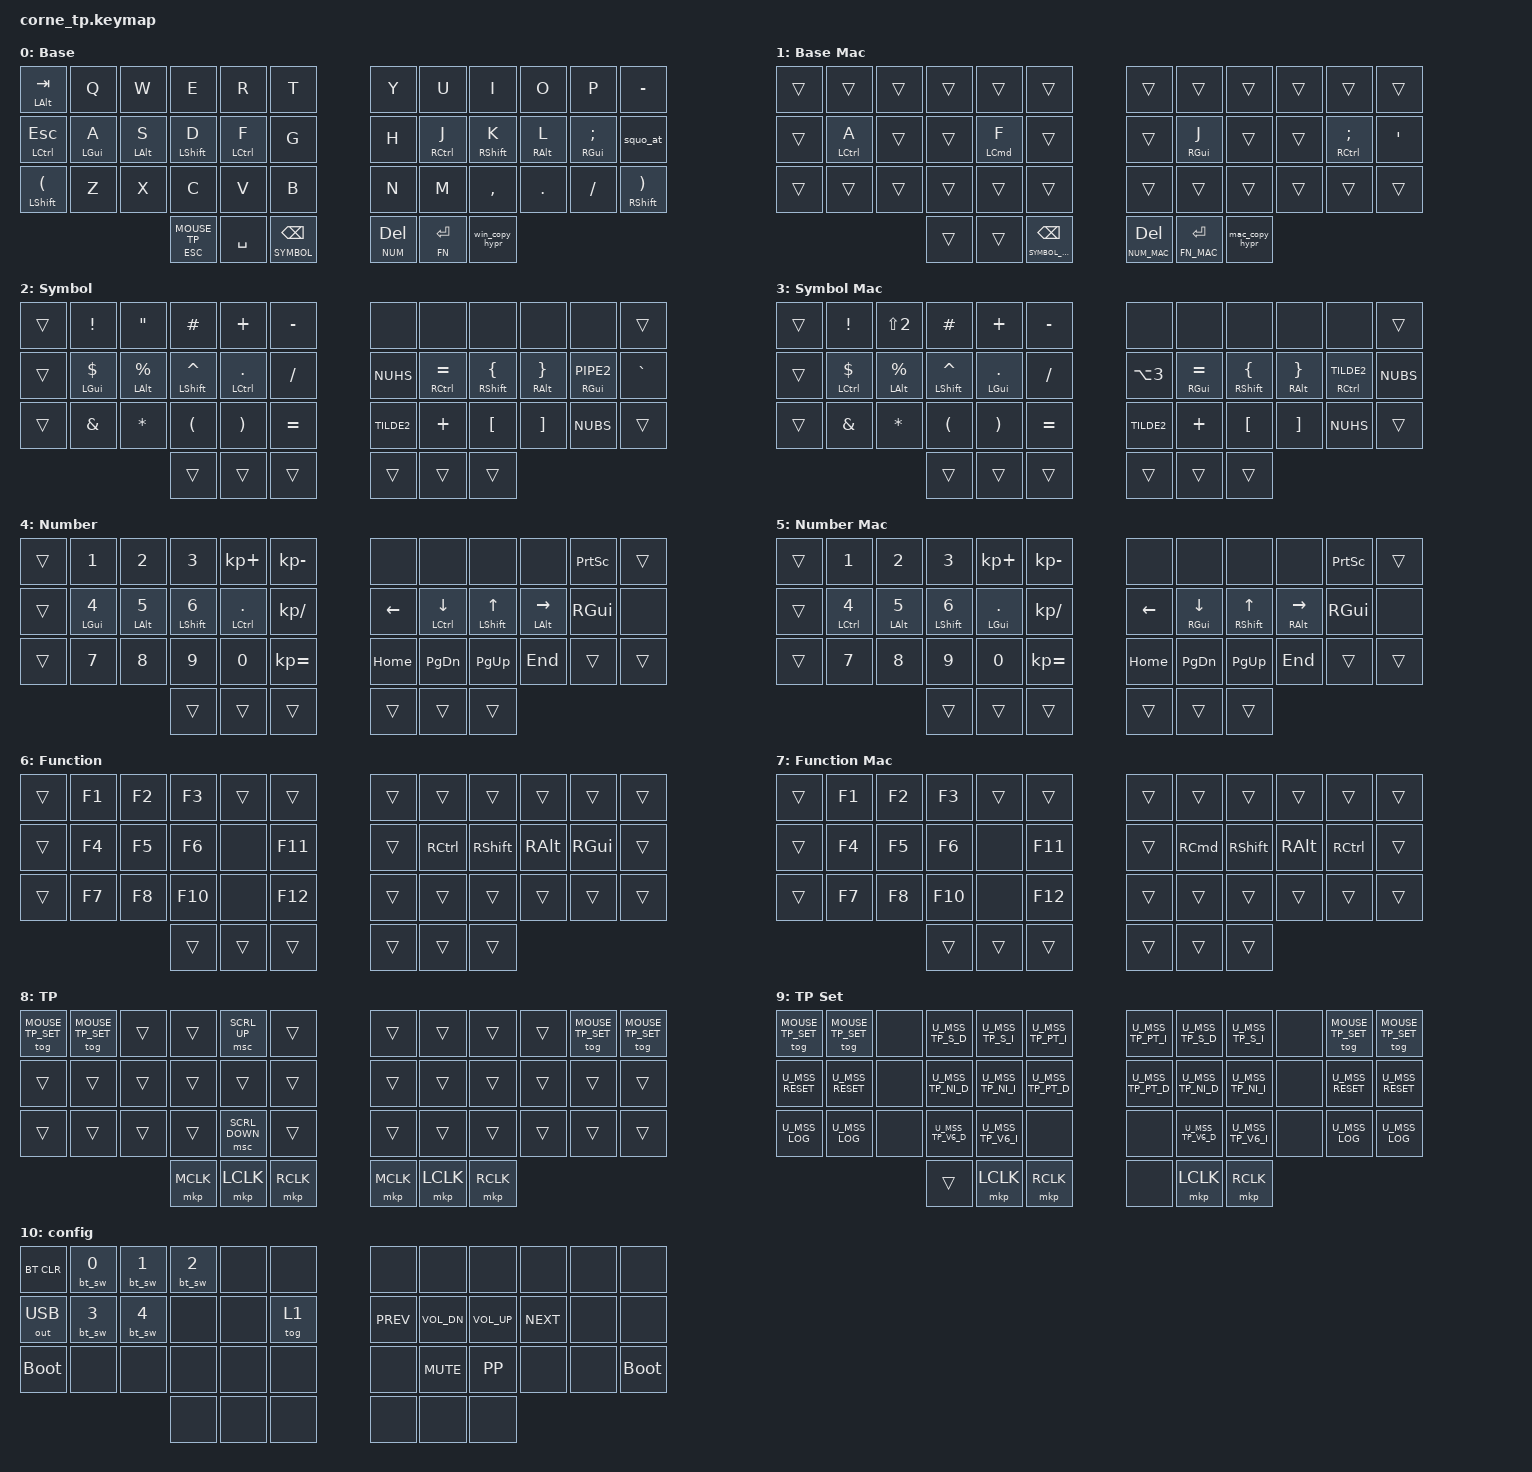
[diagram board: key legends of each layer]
/*
 * Copyright (c) 2020 The ZMK Contributors
 *
 * SPDX-License-Identifier: MIT
 */

#include <behaviors.dtsi>
#include <dt-bindings/zmk/keys.h>
#include <dt-bindings/zmk/bt.h>
#include <dt-bindings/zmk/outputs.h>

#define BASE 0
#define BASE_MAC 1
#define SYMBOL 2
#define SYMBOL_MAC 3
#define NUM 4
#define NUM_MAC 5
#define FN 6
#define FN_MAC 7
#define MOUSE_TP 8
#define MOUSE_TP_SET 9
#define CONFIG 10

/*
 * Defines to enable/disable features
 *
 * These defines allow us to conditionally enable and disable parts of the keymap config.
 *
 * For example, if we decide to build the firmware without the mouse features, we can
 * disable all the config options that rely on those forks and modules without having
 * to edit the entire keymap file manually every time.
 */

#define HAS_MOUSE_KEYS
#define HAS_MOUSE_TP

#ifdef HAS_MOUSE_KEYS
  #include <dt-bindings/zmk/mouse.h>
  #include <behaviors/mouse_keys.dtsi>
#endif  // HAS_MOUSE_KEYS

#ifdef HAS_MOUSE_TP
  // We store the trackpoint settings in a separate file
  // to make organization a little easier.
  #include "include/mouse_tp.dtsi"
#endif  // HAS_MOUSE_TP



// Adjust layer keys based on enabled features.
//
// This prevents build errors when we build the firmware
// without the mouse keys PR or the TP module.
#ifdef HAS_MOUSE_KEYS
  #define U_THUMB_INNER &mo MOUSE_KEYS
#else
  #define U_THUMB_INNER &none
#endif  // HAS_MOUSE_KEYS

#ifdef HAS_MOUSE_TP
  #define U_TOG_TP_SET &tog MOUSE_TP_SET
#else
  #define U_TOG_TP_SET &none
#endif  // HAS_MOUSE_TP

&mt {
    flavor = "tap-preferred";
    require-prior-idle-ms = <100>;
    quick-tap-ms = <80>;
};

&lt {
    quick-tap-ms = <80>;
    require-prior-idle-ms = <0>;
    flavor = "hold-preferred";
};
// Disable line-wrap in your editor to see a "visualization" of the key layouts
/ {
     behaviors {
        squo_at: squo_at {
            compatible = "zmk,behavior-mod-morph";
            label = "SQUO_AT";
            bindings = <&kp SQT>, <&kp LS(N2)>;

            #binding-cells = <0>;
            mods = <(MOD_LSFT|MOD_RSFT)>;
        };

        win_copy_hypr: win_copy_hypr {
            compatible = "zmk,behavior-tap-dance";
            label = "WIN_COPY_HYPR";
            #binding-cells = <0>;
            bindings = <&mt LS(LA(LC(LGUI))) LC(C)>, <&kp LC(V)>;
        };

        mac_copy_hypr: mac_copy_hypr {
            compatible = "zmk,behavior-tap-dance";
            label = "MAC_COPY_HYPR";
            #binding-cells = <0>;
            bindings = <&mt LS(LA(LC(LGUI))) LG(C)>, <&kp LG(V)>;
        };

        squo_at_mac: squo_at_mac {
            compatible = "zmk,behavior-mod-morph";
            label = "SQUO_AT_MAC";
            bindings = <&kp SQT>, <&kp N2>;

            #binding-cells = <0>;
            mods = <(MOD_LSFT|MOD_RSFT)>;
        };
    };

    macros {
        bt_sw: bt_sw {
            compatible = "zmk,behavior-macro-one-param";
            #binding-cells = <1>;
            bindings = <&out OUT_BLE>, <&macro_param_1to2>, <&bt BT_SEL MACRO_PLACEHOLDER>;
            label = "BT_SW";
        };
    };
     
     conditional_layers {
        compatible = "zmk,conditional-layers";

        config_layer {
            if-layers = <SYMBOL NUM>;
            then-layer = <CONFIG>;
        };

        config_layer_mac {
            if-layers = <SYMBOL_MAC NUM_MAC>;
            then-layer = <CONFIG>;
        };
    };

  keymap {
    compatible = "zmk,keymap";

    base {
     display-name = "Base";
                 bindings = <
&mt LALT TAB    &kp Q       &kp W       &kp E        &kp R        &kp T              &kp Y         &kp U        &kp I           &kp O       &kp P          &kp MINUS
&mt LCTRL ESC   &mt LGUI A  &mt LALT S  &mt LSHFT D  &mt LCTRL F  &kp G              &kp H         &mt RCTRL J  &mt RSHFT K     &mt RALT L  &mt RGUI SEMI  &squo_at
&mt LSHFT LPAR  &kp Z       &kp X       &kp C        &kp V        &kp B              &kp N         &kp M        &kp COMMA       &kp DOT     &kp FSLH       &mt RSHFT RPAR
                                        &lt ESC MOUSE_TP      &kp SPACE    &lt SYMBOL BACKSPACE    &lt NUM DELETE  &lt FN ENTER  &win_copy_hypr
            >;
    };

    base_mac {
     display-name = "Base Mac";
                 bindings = <
&trans  &trans       &trans  &trans  &trans      &trans             &trans     &trans       &trans          &trans  &trans               &trans
&trans  &mt LCTRL A  &trans  &trans  &mt LCMD F  &trans             &trans     &mt RGUI J   &trans          &trans  &mt RCTRL SEMICOLON  &kp SINGLE_QUOTE
&trans  &trans       &trans  &trans  &trans      &trans             &trans     &trans       &trans          &trans  &trans               &trans
                             &trans  &trans      &lt SYMBOL_MAC BACKSPACE    &lt NUM_MAC DEL  &lt FN_MAC ENTER  &mac_copy_hypr
            >;
    };

    symbol {
     display-name = "Symbol";
                 bindings = <
&trans  &kp EXCL       &kp DQT &kp HASH              &kp PLUS       &kp MINUS    &none       &none            &none           &none          &none           &trans
&trans  &mt LGUI DLLR  &mt LALT PRCNT    &mt LEFT_SHIFT CARET  &mt LCTRL DOT  &kp FSLH     &kp NUHS    &mt RCTRL EQUAL  &mt RSHFT LBRC  &mt RALT RBRC  &mt RGUI PIPE2  &kp GRAVE
&trans  &kp AMPS       &kp STAR          &kp LPAR              &kp RPAR       &kp EQUAL    &kp TILDE2  &kp PLUS         &kp LBKT        &kp RBKT       &kp NUBS        &trans
                                         &trans                &trans         &trans       &trans      &trans           &trans
            >;
    };

    symbol_mac {
     display-name = "Symbol Mac";
            bindings = <
&trans  &kp EXCL        &kp LS(NUMBER_2)  &kp HASH              &kp PLUS      &kp MINUS    &none       &none           &none           &none          &none             &trans
&trans  &mt LCTRL DLLR  &mt LALT PRCNT     &mt LEFT_SHIFT CARET  &mt LGUI DOT  &kp FSLH     &kp LA(N3)  &mt RGUI EQUAL  &mt RSHFT LBRC  &mt RALT RBRC  &mt RCTRL TILDE2  &kp NUBS
&trans  &kp AMPS        &kp STAR           &kp LPAR              &kp RPAR      &kp EQUAL    &kp TILDE2  &kp PLUS        &kp LBKT        &kp RBKT       &kp NUHS          &trans
                                           &trans                &trans        &trans       &trans      &trans          &trans
            >;
    };

    number {
     display-name = "Number";
                 bindings = <
&trans  &kp N1       &kp N2       &kp N3         &kp KP_PLUS    &kp KP_MINUS    &none     &none           &none          &none               &kp PRINTSCREEN  &trans
&trans  &mt LGUI N4  &mt LALT N5  &mt LSHIFT N6  &mt LCTRL DOT  &kp KP_SLASH    &kp LEFT  &mt LCTRL DOWN  &mt LSHIFT UP  &mt LEFT_ALT RIGHT  &kp RGUI         &none
&trans  &kp N7       &kp N8       &kp N9         &kp N0         &kp KP_EQUAL    &kp HOME  &kp PG_DN       &kp PG_UP      &kp END             &trans           &trans
                                  &trans         &trans         &trans          &trans    &trans          &trans
            >;
    };

    number_mac {
     display-name = "Number Mac";
                 bindings = <
&trans  &kp N1        &kp N2       &kp N3         &kp KP_PLUS   &kp KP_MINUS    &none     &none          &none          &none           &kp PRINTSCREEN  &trans
&trans  &mt LCTRL N4  &mt LALT N5  &mt LSHIFT N6  &mt LGUI DOT  &kp KP_SLASH    &kp LEFT  &mt RGUI DOWN  &mt RSHIFT UP  &mt RALT RIGHT  &kp RGUI         &none
&trans  &kp N7        &kp N8       &kp N9         &kp N0        &kp KP_EQUAL    &kp HOME  &kp PG_DN      &kp PG_UP      &kp END         &trans           &trans
                                   &trans         &trans        &trans          &trans    &trans         &trans
            >;
    };

    fn {
     display-name = "Function";
                 bindings = <
&trans  &kp F1  &kp F2  &kp F3   &trans  &trans     &trans  &trans     &trans     &trans    &trans    &trans
&trans  &kp F4  &kp F5  &kp F6   &none   &kp F11    &trans  &kp RCTRL  &kp RSHFT  &kp RALT  &kp RGUI  &trans
&trans  &kp F7  &kp F8  &kp F10  &none   &kp F12    &trans  &trans     &trans     &trans    &trans    &trans
                        &trans   &trans  &trans     &trans  &trans     &trans
            >;
    };

    fn_mac {
     display-name = "Function Mac";
                 bindings = <
&trans  &kp F1  &kp F2  &kp F3   &trans  &trans     &trans  &trans    &trans     &trans    &trans     &trans
&trans  &kp F4  &kp F5  &kp F6   &none   &kp F11    &trans  &kp RCMD  &kp RSHFT  &kp RALT  &kp RCTRL  &trans
&trans  &kp F7  &kp F8  &kp F10  &none   &kp F12    &trans  &trans    &trans     &trans    &trans     &trans
                        &trans   &trans  &trans     &trans  &trans    &trans
            >;
    };

     MouseTP_layer {
      display-name = "TP";
      bindings = <
// ╭────────────────────────┬────────────────────────┬────────────────────────┬────────────────────────┬────────────────────────┬────────────────────────╮    ╭────────────────────────┬────────────────────────┬────────────────────────┬────────────────────────┬────────────────────────┬────────────────────────╮
     U_TOG_TP_SET             U_TOG_TP_SET             &trans                   &trans                   &msc SCRL_UP             &trans                        &trans                   &trans                   &trans                   &trans                   U_TOG_TP_SET              U_TOG_TP_SET
// ├────────────────────────┼────────────────────────┼────────────────────────┼────────────────────────┼────────────────────────┼────────────────────────┤    ├────────────────────────┼────────────────────────┼────────────────────────┼────────────────────────┼────────────────────────┼────────────────────────┤
     &trans                   &trans                   &trans                   &trans                   &trans                   &trans                        &trans                   &trans                   &trans                   &trans                   &trans                    &trans
// ├────────────────────────┼────────────────────────┼────────────────────────┼────────────────────────┼────────────────────────┼────────────────────────┤    ├────────────────────────┼────────────────────────┼────────────────────────┼────────────────────────┼────────────────────────┼────────────────────────┤
     &trans                   &trans                   &trans                   &trans                   &msc SCRL_DOWN           &trans                        &trans                   &trans                   &trans                   &trans                   &trans                    &trans
// ╰────────────────────────┴────────────────────────┴────────────────────────┴────────────────────────┼────────────────────────┼────────────────────────┤    ├────────────────────────┼────────────────────────┼────────────────────────┼────────────────────────┴────────────────────────┼────────────────────────╯
                                                                                &mkp MCLK                &mkp LCLK                &mkp RCLK                     &mkp MCLK                &mkp LCLK                &mkp RCLK
//                                                                            ╰────────────────────────┴────────────────────────┴────────────────────────╯    ╰────────────────────────┴────────────────────────┴────────────────────────╯
      >;
    };

    // You can find the defines for the actual key press behaviors in `include/mouse_tp.dtsi`.
    MouseSettings_layer {
      display-name = "TP Set";
      bindings = <
// ╭────────────────────────┬────────────────────────┬────────────────────────┬────────────────────────┬────────────────────────┬────────────────────────╮    ╭────────────────────────┬────────────────────────┬────────────────────────┬────────────────────────┬────────────────────────┬────────────────────────╮
     U_TOG_TP_SET             U_TOG_TP_SET             &none                    U_MSS_TP_S_D             U_MSS_TP_S_I             U_MSS_TP_PT_I                 U_MSS_TP_PT_I            U_MSS_TP_S_D             U_MSS_TP_S_I             &none                    U_TOG_TP_SET              U_TOG_TP_SET
// ├────────────────────────┼────────────────────────┼────────────────────────┼────────────────────────┼────────────────────────┼────────────────────────┤    ├────────────────────────┼────────────────────────┼────────────────────────┼────────────────────────┼────────────────────────┼────────────────────────┤
     U_MSS_RESET              U_MSS_RESET              &none                    U_MSS_TP_NI_D            U_MSS_TP_NI_I            U_MSS_TP_PT_D                 U_MSS_TP_PT_D            U_MSS_TP_NI_D            U_MSS_TP_NI_I            &none                    U_MSS_RESET               U_MSS_RESET
// ├────────────────────────┼────────────────────────┼────────────────────────┼────────────────────────┼────────────────────────┼────────────────────────┤    ├────────────────────────┼────────────────────────┼────────────────────────┼────────────────────────┼────────────────────────┼────────────────────────┤
     U_MSS_LOG                U_MSS_LOG                &none                    U_MSS_TP_V6_D            U_MSS_TP_V6_I            &none                         &none                    U_MSS_TP_V6_D            U_MSS_TP_V6_I            &none                    U_MSS_LOG                 U_MSS_LOG
// ╰────────────────────────┴────────────────────────┴────────────────────────┴────────────────────────┼────────────────────────┼────────────────────────┤    ├────────────────────────┼────────────────────────┼────────────────────────┼────────────────────────┴────────────────────────┼────────────────────────╯
                                                                                &trans                   &mkp LCLK                &mkp RCLK                     &none                    &mkp LCLK                &mkp RCLK
//                                                                            ╰────────────────────────┴────────────────────────┴────────────────────────╯    ╰────────────────────────┴────────────────────────┴────────────────────────╯
      >;
    };

    config {
     display-name = "config";
                 bindings = <
&bt BT_CLR    &bt_sw 0  &bt_sw 1  &bt_sw 2  &none  &none     &none       &none         &none         &none       &none  &none
&out OUT_USB  &bt_sw 3  &bt_sw 4  &none     &none  &tog 1    &kp K_PREV  &kp K_VOL_DN  &kp K_VOL_UP  &kp K_NEXT  &none  &none
&bootloader   &none     &none     &none     &none  &none     &none       &kp K_MUTE    &kp K_PP      &none       &none  &bootloader
                                  &none     &none  &none     &none       &none         &none
            >;
    };

  };
};
